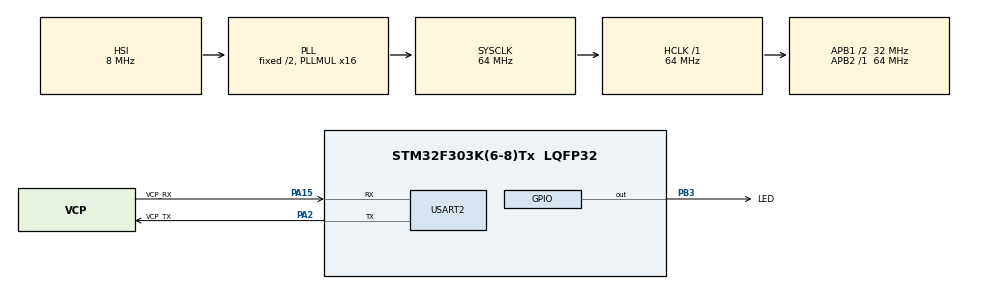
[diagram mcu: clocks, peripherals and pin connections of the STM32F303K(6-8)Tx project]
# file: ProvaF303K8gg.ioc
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Mcu.Family=STM32F3
RCC.CortexFreq_Value=64000000
PF0\ /\ OSC_IN.Mode=HSE-External-Clock-Source
PA14.GPIO_Label=SWCLK
RCC.SYSCLKSourceVirtual=RCC_SYSCLKSOURCE_PLLCLK
RCC.APB1CLKDivider=RCC_HCLK_DIV2
ProjectManager.StackSize=0x400
PA13.Signal=SYS_JTMS-SWDIO
PA15.GPIO_Label=VCP_RX
ProjectManager.TargetToolchain=STM32CubeIDE
RCC.HCLKFreq_Value=64000000
RCC.APB2TimFreq_Value=64000000
RCC.AHBFreq_Value=64000000
RCC.HSE_VALUE=8000000
board=NUCLEO-F303K8
USART2.VirtualMode-Asynchronous=VM_ASYNC
PA15.Mode=Asynchronous
RCC.PLLMUL=RCC_PLL_MUL16
RCC.APB2Freq_Value=64000000
PF0\ /\ OSC_IN.Signal=RCC_OSC_IN
PA14.Mode=Serial_Wire
PF0\ /\ OSC_IN.GPIO_Label=MCO
PA13.Mode=Serial_Wire
Mcu.Name=STM32F303K(6-8)Tx
PA13.GPIO_Label=SWDIO
PA2.Signal=USART2_TX
PB3.Signal=GPIO_Output
RCC.SYSCLKFreq_VALUE=64000000
Mcu.Package=LQFP32
PA2.GPIO_Label=VCP_TX
PA14.Signal=SYS_JTCK-SWCLK
PA15.Signal=USART2_RX
ProjectManager.HeapSize=0x200
RCC.HSI_VALUE=8000000
NVIC.PriorityGroup=NVIC_PRIORITYGROUP_4
RCC.APB1TimFreq_Value=64000000
PA2.Mode=Asynchronous
RCC.APB1Freq_Value=32000000
PB3.GPIO_Label=LED

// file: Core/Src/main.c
/* USER CODE BEGIN Header */
/**
  ******************************************************************************
  * @file           : main.c
  * @brief          : Main program body
  ******************************************************************************
  * @attention
  *
  * <h2><center>&copy; Copyright (c) 2021 STMicroelectronics.
  * All rights reserved.</center></h2>
  *
  * This software component is licensed by ST under BSD 3-Clause license,
  * the "License"; You may not use this file except in compliance with the
  * License. You may obtain a copy of the License at:
  *                        opensource.org/licenses/BSD-3-Clause
  *
  ******************************************************************************
  */
/* USER CODE END Header */
#include "main.h"

/* USER CODE BEGIN Includes */
#include <string.h>
#include <stdio.h>
/* USER CODE END Includes */

UART_HandleTypeDef huart2;

void SystemClock_Config(void);
static void MX_GPIO_Init(void);
static void MX_USART2_UART_Init(void);

int main(void)
{

  /* MCU Configuration--------------------------------------------------------*/

  /* Reset of all peripherals, Initializes the Flash interface and the Systick. */
  HAL_Init();

  /* Configure the system clock */
  SystemClock_Config();

  /* Initialize all configured peripherals */
  MX_GPIO_Init();
  MX_USART2_UART_Init();

  /* Infinite loop */
  /* USER CODE BEGIN WHILE */
  char *msg = "Prova; %d\n";
  char buffer[30];
  int i = 0;
  while (1)
  {
	sprintf(buffer,msg,i++);
	HAL_UART_Transmit(&huart2, (uint8_t*)buffer, strlen(msg), HAL_MAX_DELAY);
	HAL_GPIO_TogglePin(LED_GPIO_Port, LED_Pin);
	HAL_Delay(1000);
    /* USER CODE END WHILE */

  }
}

void SystemClock_Config(void)
{
  RCC_OscInitTypeDef RCC_OscInitStruct = {0};
  RCC_ClkInitTypeDef RCC_ClkInitStruct = {0};

  /** Initializes the RCC Oscillators according to the specified parameters
  * in the RCC_OscInitTypeDef structure.
  */
  RCC_OscInitStruct.OscillatorType = RCC_OSCILLATORTYPE_HSI;
  RCC_OscInitStruct.HSIState = RCC_HSI_ON;
  RCC_OscInitStruct.HSICalibrationValue = RCC_HSICALIBRATION_DEFAULT;
  RCC_OscInitStruct.PLL.PLLState = RCC_PLL_ON;
  RCC_OscInitStruct.PLL.PLLSource = RCC_PLLSOURCE_HSI;
  RCC_OscInitStruct.PLL.PLLMUL = RCC_PLL_MUL16;
  if (HAL_RCC_OscConfig(&RCC_OscInitStruct) != HAL_OK)
  {
    Error_Handler();
  }
  /** Initializes the CPU, AHB and APB buses clocks
  */
  RCC_ClkInitStruct.ClockType = RCC_CLOCKTYPE_HCLK|RCC_CLOCKTYPE_SYSCLK
                              |RCC_CLOCKTYPE_PCLK1|RCC_CLOCKTYPE_PCLK2;
  RCC_ClkInitStruct.SYSCLKSource = RCC_SYSCLKSOURCE_PLLCLK;
  RCC_ClkInitStruct.AHBCLKDivider = RCC_SYSCLK_DIV1;
  RCC_ClkInitStruct.APB1CLKDivider = RCC_HCLK_DIV2;
  RCC_ClkInitStruct.APB2CLKDivider = RCC_HCLK_DIV1;

  if (HAL_RCC_ClockConfig(&RCC_ClkInitStruct, FLASH_LATENCY_2) != HAL_OK)
  {
    Error_Handler();
  }
}

static void MX_USART2_UART_Init(void)
{

  huart2.Instance = USART2;
  huart2.Init.BaudRate = 38400;
  huart2.Init.WordLength = UART_WORDLENGTH_8B;
  huart2.Init.StopBits = UART_STOPBITS_1;
  huart2.Init.Parity = UART_PARITY_NONE;
  huart2.Init.Mode = UART_MODE_TX_RX;
  huart2.Init.HwFlowCtl = UART_HWCONTROL_NONE;
  huart2.Init.OverSampling = UART_OVERSAMPLING_16;
  huart2.Init.OneBitSampling = UART_ONE_BIT_SAMPLE_DISABLE;
  huart2.AdvancedInit.AdvFeatureInit = UART_ADVFEATURE_NO_INIT;
  if (HAL_UART_Init(&huart2) != HAL_OK)
  {
    Error_Handler();
  }

}

static void MX_GPIO_Init(void)
{
  GPIO_InitTypeDef GPIO_InitStruct = {0};

  /* GPIO Ports Clock Enable */
  __HAL_RCC_GPIOF_CLK_ENABLE();
  __HAL_RCC_GPIOA_CLK_ENABLE();
  __HAL_RCC_GPIOB_CLK_ENABLE();

  /*Configure GPIO pin Output Level */
  HAL_GPIO_WritePin(LED_GPIO_Port, LED_Pin, GPIO_PIN_RESET);

  /*Configure GPIO pin : LED_Pin */
  GPIO_InitStruct.Pin = LED_Pin;
  GPIO_InitStruct.Mode = GPIO_MODE_OUTPUT_PP;
  GPIO_InitStruct.Pull = GPIO_NOPULL;
  GPIO_InitStruct.Speed = GPIO_SPEED_FREQ_LOW;
  HAL_GPIO_Init(LED_GPIO_Port, &GPIO_InitStruct);

}

void Error_Handler(void)
{
  __disable_irq();
  while (1)
  {
  }
}

/************************ (C) COPYRIGHT STMicroelectronics *****END OF FILE****/
